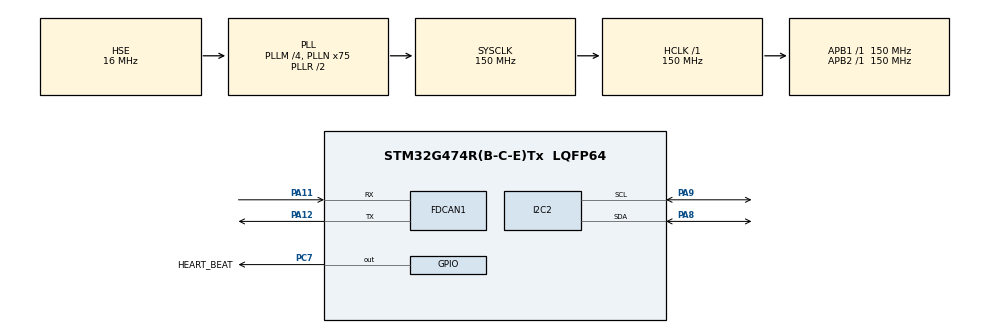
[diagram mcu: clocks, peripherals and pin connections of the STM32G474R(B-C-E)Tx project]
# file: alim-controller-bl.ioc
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FDCAN1.CalculateBaudRateNominal=2000000
FDCAN1.CalculateTimeBitNominal=500
FDCAN1.CalculateTimeQuantumNominal=100.0
FDCAN1.NominalPrescaler=15
FDCAN1.NominalTimeSeg1=2
FDCAN1.NominalTimeSeg2=2
FDCAN1.StdFiltersNbr=1
I2C2.Timing=0x30D293D6
Mcu.Family=STM32G4
Mcu.Name=STM32G474R(B-C-E)Tx
Mcu.Package=LQFP64
NVIC.PriorityGroup=NVIC_PRIORITYGROUP_4
NVIC.TIM1_UP_TIM16_IRQn=true\:15\:0\:false\:false\:true\:false\:true\:true
NVIC.TimeBase=TIM1_UP_TIM16_IRQn
NVIC.TimeBaseIP=TIM1
PA11.Mode=FDCAN_Activate
PA11.Signal=FDCAN1_RX
PA12.Mode=FDCAN_Activate
PA12.Signal=FDCAN1_TX
PA13.Mode=Trace_Asynchronous_SW
PA13.Signal=SYS_JTMS-SWDIO
PA14.Mode=Trace_Asynchronous_SW
PA14.Signal=SYS_JTCK-SWCLK
PA8.Mode=I2C
PA8.Signal=I2C2_SDA
PA9.Mode=I2C
PA9.Signal=I2C2_SCL
PB3.Mode=Trace_Asynchronous_SW
PB3.Signal=SYS_JTDO-SWO
PC7.GPIO_Label=HEART_BEAT
PC7.Signal=GPIO_Output
PF0-OSC_IN.Mode=HSE-External-Oscillator
PF0-OSC_IN.Signal=RCC_OSC_IN
PF1-OSC_OUT.Mode=HSE-External-Oscillator
PF1-OSC_OUT.Signal=RCC_OSC_OUT
ProjectManager.HeapSize=0x200
ProjectManager.StackSize=0x400
ProjectManager.TargetToolchain=CMake
RCC.ADC12Freq_Value=150000000
RCC.ADC345Freq_Value=150000000
RCC.AHBFreq_Value=150000000
RCC.APB1Freq_Value=150000000
RCC.APB1TimFreq_Value=150000000
RCC.APB2Freq_Value=150000000
RCC.APB2TimFreq_Value=150000000
RCC.CortexFreq_Value=150000000
RCC.EXTERNAL_CLOCK_VALUE=12288000
RCC.HCLKFreq_Value=150000000
RCC.HSE_VALUE=16000000
RCC.HSI48_VALUE=48000000
RCC.HSI_VALUE=16000000
RCC.LSE_VALUE=32768
RCC.PLLM=RCC_PLLM_DIV4
RCC.PLLN=75
RCC.PLLSourceVirtual=RCC_PLLSOURCE_HSE
RCC.SYSCLKFreq_VALUE=150000000
RCC.SYSCLKSource=RCC_SYSCLKSOURCE_PLLCLK
RCC.USBFreq_Value=150000000
RCC.VCOOutputFreq_Value=300000000
VP_SYS_VS_DBSignals.Mode=DisableDeadBatterySignals
VP_SYS_VS_tim1.Mode=TIM1
board=custom

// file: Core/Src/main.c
/* USER CODE BEGIN Header */
/**
  ******************************************************************************
  * @file           : main.c
  * @brief          : Main program body
  ******************************************************************************
  * @attention
  *
  * Copyright (c) 2026 STMicroelectronics.
  * All rights reserved.
  *
  * This software is licensed under terms that can be found in the LICENSE file
  * in the root directory of this software component.
  * If no LICENSE file comes with this software, it is provided AS-IS.
  *
  ******************************************************************************
  */
/* USER CODE END Header */
#include "main.h"
#include "fdcan.h"
#include "i2c.h"
#include "gpio.h"

/* USER CODE BEGIN Includes */
#include "app_openbootloader.h"
#include "openbl_mem.h"
/* USER CODE END Includes */

void SystemClock_Config(void);

/* USER CODE BEGIN 0 */
void System_DeInit(void)
{
  HAL_RCC_DeInit();
}
/* USER CODE END 0 */

int main(void)
{

  /* MCU Configuration--------------------------------------------------------*/

  /* Reset of all peripherals, Initializes the Flash interface and the Systick. */
  HAL_Init();

  /* Configure the system clock */
  SystemClock_Config();

  /* Initialize all configured peripherals */
  MX_GPIO_Init();
  MX_FDCAN1_Init();
  MX_I2C2_Init();
  /* USER CODE BEGIN 2 */
  OpenBootloader_Init();
  /* USER CODE END 2 */

  /* Infinite loop */
  while (1)
  {

    /* USER CODE BEGIN 3 */
    OpenBootloader_ProtocolDetection();

    if (HAL_GetTick() > 10000) {
      // TODO: Use a constant
      OPENBL_MEM_JumpToAddress(0x08008000);
    }

  }
  /* USER CODE END 3 */
}

void SystemClock_Config(void)
{
  RCC_OscInitTypeDef RCC_OscInitStruct = {0};
  RCC_ClkInitTypeDef RCC_ClkInitStruct = {0};

  /** Configure the main internal regulator output voltage
  */
  HAL_PWREx_ControlVoltageScaling(PWR_REGULATOR_VOLTAGE_SCALE1);

  /** Initializes the RCC Oscillators according to the specified parameters
  * in the RCC_OscInitTypeDef structure.
  */
  RCC_OscInitStruct.OscillatorType = RCC_OSCILLATORTYPE_HSE;
  RCC_OscInitStruct.HSEState = RCC_HSE_ON;
  RCC_OscInitStruct.PLL.PLLState = RCC_PLL_ON;
  RCC_OscInitStruct.PLL.PLLSource = RCC_PLLSOURCE_HSE;
  RCC_OscInitStruct.PLL.PLLM = RCC_PLLM_DIV4;
  RCC_OscInitStruct.PLL.PLLN = 75;
  RCC_OscInitStruct.PLL.PLLP = RCC_PLLP_DIV2;
  RCC_OscInitStruct.PLL.PLLQ = RCC_PLLQ_DIV2;
  RCC_OscInitStruct.PLL.PLLR = RCC_PLLR_DIV2;
  if (HAL_RCC_OscConfig(&RCC_OscInitStruct) != HAL_OK)
  {
    Error_Handler();
  }

  /** Initializes the CPU, AHB and APB buses clocks
  */
  RCC_ClkInitStruct.ClockType = RCC_CLOCKTYPE_HCLK|RCC_CLOCKTYPE_SYSCLK
                              |RCC_CLOCKTYPE_PCLK1|RCC_CLOCKTYPE_PCLK2;
  RCC_ClkInitStruct.SYSCLKSource = RCC_SYSCLKSOURCE_PLLCLK;
  RCC_ClkInitStruct.AHBCLKDivider = RCC_SYSCLK_DIV1;
  RCC_ClkInitStruct.APB1CLKDivider = RCC_HCLK_DIV1;
  RCC_ClkInitStruct.APB2CLKDivider = RCC_HCLK_DIV1;

  if (HAL_RCC_ClockConfig(&RCC_ClkInitStruct, FLASH_LATENCY_4) != HAL_OK)
  {
    Error_Handler();
  }
}

void HAL_TIM_PeriodElapsedCallback(TIM_HandleTypeDef *htim)
{
  if (htim->Instance == TIM1)
  {
    HAL_IncTick();
  }
}

void Error_Handler(void)
{
  __disable_irq();
  while (1)
  {
  }
}
